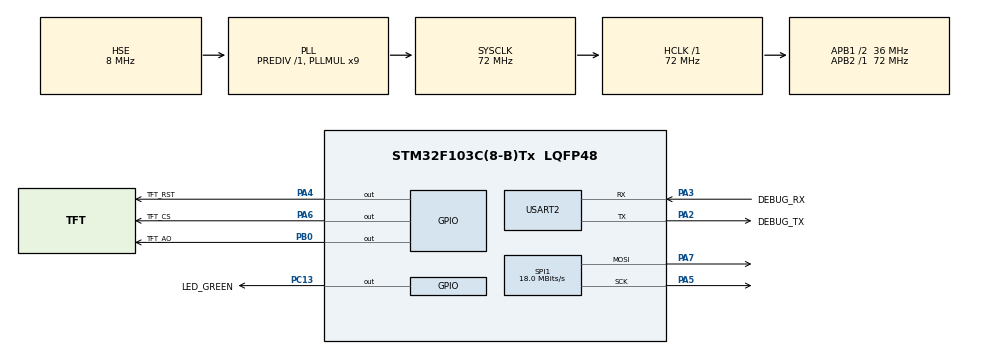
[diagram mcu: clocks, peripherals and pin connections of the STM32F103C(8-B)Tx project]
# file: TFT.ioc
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Mcu.Family=STM32F1
Mcu.Name=STM32F103C(8-B)Tx
Mcu.Package=LQFP48
NVIC.PriorityGroup=NVIC_PRIORITYGROUP_4
PA13.Mode=Serial_Wire
PA13.Signal=SYS_JTMS-SWDIO
PA14.Mode=Serial_Wire
PA14.Signal=SYS_JTCK-SWCLK
PA2.GPIO_Label=DEBUG_TX
PA2.Mode=Asynchronous
PA2.Signal=USART2_TX
PA3.GPIO_Label=DEBUG_RX
PA3.Mode=Asynchronous
PA3.Signal=USART2_RX
PA4.GPIO_Label=TFT_RST
PA4.GPIO_Speed=GPIO_SPEED_FREQ_HIGH
PA4.Signal=GPIO_Output
PA5.Mode=TX_Only_Simplex_Unidirect_Master
PA5.Signal=SPI1_SCK
PA6.GPIO_Label=TFT_CS
PA6.GPIO_Speed=GPIO_SPEED_FREQ_HIGH
PA6.Signal=GPIO_Output
PA7.Mode=TX_Only_Simplex_Unidirect_Master
PA7.Signal=SPI1_MOSI
PB0.GPIO_Label=TFT_AO
PB0.GPIO_Speed=GPIO_SPEED_FREQ_HIGH
PB0.Signal=GPIO_Output
PC13-TAMPER-RTC.GPIO_Label=LED_GREEN
PC13-TAMPER-RTC.GPIO_Speed=GPIO_SPEED_FREQ_HIGH
PC13-TAMPER-RTC.Signal=GPIO_Output
PC14-OSC32_IN.Mode=LSE-External-Oscillator
PC14-OSC32_IN.Signal=RCC_OSC32_IN
PC15-OSC32_OUT.Mode=LSE-External-Oscillator
PC15-OSC32_OUT.Signal=RCC_OSC32_OUT
PD0-OSC_IN.Mode=HSE-External-Oscillator
PD0-OSC_IN.Signal=RCC_OSC_IN
PD1-OSC_OUT.Mode=HSE-External-Oscillator
PD1-OSC_OUT.Signal=RCC_OSC_OUT
ProjectManager.HeapSize=0x200
ProjectManager.StackSize=0x400
ProjectManager.TargetToolchain=EWARM
RCC.AHBFreq_Value=72000000
RCC.APB1CLKDivider=RCC_HCLK_DIV2
RCC.APB1Freq_Value=36000000
RCC.APB1TimFreq_Value=72000000
RCC.APB2Freq_Value=72000000
RCC.APB2TimFreq_Value=72000000
RCC.HCLKFreq_Value=72000000
RCC.PLLMUL=RCC_PLL_MUL9
RCC.PLLSourceVirtual=RCC_PLLSOURCE_HSE
RCC.SYSCLKFreq_VALUE=72000000
RCC.SYSCLKSource=RCC_SYSCLKSOURCE_PLLCLK
RCC.USBFreq_Value=48000000
RCC.USBPrescaler=RCC_USBCLKSOURCE_PLL_DIV1_5
SPI1.BaudRatePrescaler=SPI_BAUDRATEPRESCALER_4
SPI1.CLKPhase=SPI_PHASE_2EDGE
SPI1.CLKPolarity=SPI_POLARITY_HIGH
SPI1.CalculateBaudRate=18.0 MBits/s
SPI1.Direction=SPI_DIRECTION_2LINES
SPI1.Mode=SPI_MODE_MASTER
SPI1.VirtualType=VM_MASTER
USART2.VirtualMode=VM_ASYNC
board=TFT

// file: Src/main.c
/**
  ******************************************************************************
  * @file           : main.c
  * @brief          : Main program body
  ******************************************************************************
  ** This notice applies to any and all portions of this file
  * that are not between comment pairs USER CODE BEGIN and
  * USER CODE END. Other portions of this file, whether
  * inserted by the user or by software development tools
  * are owned by their respective copyright owners.
  *
  * COPYRIGHT(c) 2018 STMicroelectronics
  *
  * Redistribution and use in source and binary forms, with or without modification,
  * are permitted provided that the following conditions are met:
  *   1. Redistributions of source code must retain the above copyright notice,
  *      this list of conditions and the following disclaimer.
  *   2. Redistributions in binary form must reproduce the above copyright notice,
  *      this list of conditions and the following disclaimer in the documentation
  *      and/or other materials provided with the distribution.
  *   3. Neither the name of STMicroelectronics nor the names of its contributors
  *      may be used to endorse or promote products derived from this software
  *      without specific prior written permission.
  *
  * THIS SOFTWARE IS PROVIDED BY THE COPYRIGHT HOLDERS AND CONTRIBUTORS "AS IS"
  * AND ANY EXPRESS OR IMPLIED WARRANTIES, INCLUDING, BUT NOT LIMITED TO, THE
  * IMPLIED WARRANTIES OF MERCHANTABILITY AND FITNESS FOR A PARTICULAR PURPOSE ARE
  * DISCLAIMED. IN NO EVENT SHALL THE COPYRIGHT HOLDER OR CONTRIBUTORS BE LIABLE
  * FOR ANY DIRECT, INDIRECT, INCIDENTAL, SPECIAL, EXEMPLARY, OR CONSEQUENTIAL
  * DAMAGES (INCLUDING, BUT NOT LIMITED TO, PROCUREMENT OF SUBSTITUTE GOODS OR
  * SERVICES; LOSS OF USE, DATA, OR PROFITS; OR BUSINESS INTERRUPTION) HOWEVER
  * CAUSED AND ON ANY THEORY OF LIABILITY, WHETHER IN CONTRACT, STRICT LIABILITY,
  * OR TORT (INCLUDING NEGLIGENCE OR OTHERWISE) ARISING IN ANY WAY OUT OF THE USE
  * OF THIS SOFTWARE, EVEN IF ADVISED OF THE POSSIBILITY OF SUCH DAMAGE.
  *
  ******************************************************************************
  */
#include "main.h"
#include "stm32f1xx_hal.h"

/* USER CODE BEGIN Includes */

#include "LCD.h"
/* USER CODE END Includes */

SPI_HandleTypeDef hspi1;

UART_HandleTypeDef huart2;

/* USER CODE BEGIN PV */
/* Private variables ---------------------------------------------------------*/

/* USER CODE END PV */

void SystemClock_Config(void);
static void MX_GPIO_Init(void);
static void MX_USART2_UART_Init(void);
static void MX_SPI1_Init(void);

/* USER CODE BEGIN PFP */
/* Private function prototypes -----------------------------------------------*/

/* USER CODE END PFP */

int main(void)
{

  /* MCU Configuration----------------------------------------------------------*/

  /* Reset of all peripherals, Initializes the Flash interface and the Systick. */
  HAL_Init();

  /* Configure the system clock */
  SystemClock_Config();

  /* Initialize all configured peripherals */
  MX_GPIO_Init();
  MX_USART2_UART_Init();
  MX_SPI1_Init();
  /* USER CODE BEGIN 2 */
  HAL_UART_Transmit(&huart2,"TFT LCD TEST",sizeof("TFT LCD TEST"),0xFFFF );
  LCD_Init();
  /* USER CODE END 2 */

  /* Infinite loop */
  while (1)
  {

  /* USER CODE BEGIN 3 */
  LCD_Clear(BLUE);
  HAL_Delay(1000);
  LCD_Clear(YELLOW);
  HAL_Delay(1000);
  LCD_Clear(RED);
  }
  /* USER CODE END 3 */

}

void SystemClock_Config(void)
{

  RCC_OscInitTypeDef RCC_OscInitStruct;
  RCC_ClkInitTypeDef RCC_ClkInitStruct;

    /**Initializes the CPU, AHB and APB busses clocks
    */
  RCC_OscInitStruct.OscillatorType = RCC_OSCILLATORTYPE_HSE;
  RCC_OscInitStruct.HSEState = RCC_HSE_ON;
  RCC_OscInitStruct.HSEPredivValue = RCC_HSE_PREDIV_DIV1;
  RCC_OscInitStruct.HSIState = RCC_HSI_ON;
  RCC_OscInitStruct.PLL.PLLState = RCC_PLL_ON;
  RCC_OscInitStruct.PLL.PLLSource = RCC_PLLSOURCE_HSE;
  RCC_OscInitStruct.PLL.PLLMUL = RCC_PLL_MUL9;
  if (HAL_RCC_OscConfig(&RCC_OscInitStruct) != HAL_OK)
  {
    _Error_Handler(__FILE__, __LINE__);
  }

    /**Initializes the CPU, AHB and APB busses clocks
    */
  RCC_ClkInitStruct.ClockType = RCC_CLOCKTYPE_HCLK|RCC_CLOCKTYPE_SYSCLK
                              |RCC_CLOCKTYPE_PCLK1|RCC_CLOCKTYPE_PCLK2;
  RCC_ClkInitStruct.SYSCLKSource = RCC_SYSCLKSOURCE_PLLCLK;
  RCC_ClkInitStruct.AHBCLKDivider = RCC_SYSCLK_DIV1;
  RCC_ClkInitStruct.APB1CLKDivider = RCC_HCLK_DIV2;
  RCC_ClkInitStruct.APB2CLKDivider = RCC_HCLK_DIV1;

  if (HAL_RCC_ClockConfig(&RCC_ClkInitStruct, FLASH_LATENCY_2) != HAL_OK)
  {
    _Error_Handler(__FILE__, __LINE__);
  }

    /**Configure the Systick interrupt time
    */
  HAL_SYSTICK_Config(HAL_RCC_GetHCLKFreq()/1000);

    /**Configure the Systick
    */
  HAL_SYSTICK_CLKSourceConfig(SYSTICK_CLKSOURCE_HCLK);

  /* SysTick_IRQn interrupt configuration */
  HAL_NVIC_SetPriority(SysTick_IRQn, 0, 0);
}

/* SPI1 init function */
static void MX_SPI1_Init(void)
{

  /* SPI1 parameter configuration*/
  hspi1.Instance = SPI1;
  hspi1.Init.Mode = SPI_MODE_MASTER;
  hspi1.Init.Direction = SPI_DIRECTION_2LINES;
  hspi1.Init.DataSize = SPI_DATASIZE_8BIT;
  hspi1.Init.CLKPolarity = SPI_POLARITY_HIGH;
  hspi1.Init.CLKPhase = SPI_PHASE_2EDGE;
  hspi1.Init.NSS = SPI_NSS_SOFT;
  hspi1.Init.BaudRatePrescaler = SPI_BAUDRATEPRESCALER_4;
  hspi1.Init.FirstBit = SPI_FIRSTBIT_MSB;
  hspi1.Init.TIMode = SPI_TIMODE_DISABLE;
  hspi1.Init.CRCCalculation = SPI_CRCCALCULATION_DISABLE;
  hspi1.Init.CRCPolynomial = 10;
  if (HAL_SPI_Init(&hspi1) != HAL_OK)
  {
    _Error_Handler(__FILE__, __LINE__);
  }

}

/* USART2 init function */
static void MX_USART2_UART_Init(void)
{

  huart2.Instance = USART2;
  huart2.Init.BaudRate = 115200;
  huart2.Init.WordLength = UART_WORDLENGTH_8B;
  huart2.Init.StopBits = UART_STOPBITS_1;
  huart2.Init.Parity = UART_PARITY_NONE;
  huart2.Init.Mode = UART_MODE_TX_RX;
  huart2.Init.HwFlowCtl = UART_HWCONTROL_NONE;
  huart2.Init.OverSampling = UART_OVERSAMPLING_16;
  if (HAL_UART_Init(&huart2) != HAL_OK)
  {
    _Error_Handler(__FILE__, __LINE__);
  }

}

/** Configure pins as
        * Analog
        * Input
        * Output
        * EVENT_OUT
        * EXTI
*/
static void MX_GPIO_Init(void)
{

  GPIO_InitTypeDef GPIO_InitStruct;

  /* GPIO Ports Clock Enable */
  __HAL_RCC_GPIOC_CLK_ENABLE();
  __HAL_RCC_GPIOD_CLK_ENABLE();
  __HAL_RCC_GPIOA_CLK_ENABLE();
  __HAL_RCC_GPIOB_CLK_ENABLE();

  /*Configure GPIO pin Output Level */
  HAL_GPIO_WritePin(LED_GREEN_GPIO_Port, LED_GREEN_Pin, GPIO_PIN_RESET);

  /*Configure GPIO pin Output Level */
  HAL_GPIO_WritePin(GPIOA, TFT_RST_Pin|TFT_CS_Pin, GPIO_PIN_RESET);

  /*Configure GPIO pin Output Level */
  HAL_GPIO_WritePin(TFT_AO_GPIO_Port, TFT_AO_Pin, GPIO_PIN_RESET);

  /*Configure GPIO pin : LED_GREEN_Pin */
  GPIO_InitStruct.Pin = LED_GREEN_Pin;
  GPIO_InitStruct.Mode = GPIO_MODE_OUTPUT_PP;
  GPIO_InitStruct.Speed = GPIO_SPEED_FREQ_HIGH;
  HAL_GPIO_Init(LED_GREEN_GPIO_Port, &GPIO_InitStruct);

  /*Configure GPIO pins : TFT_RST_Pin TFT_CS_Pin */
  GPIO_InitStruct.Pin = TFT_RST_Pin|TFT_CS_Pin;
  GPIO_InitStruct.Mode = GPIO_MODE_OUTPUT_PP;
  GPIO_InitStruct.Speed = GPIO_SPEED_FREQ_HIGH;
  HAL_GPIO_Init(GPIOA, &GPIO_InitStruct);

  /*Configure GPIO pin : TFT_AO_Pin */
  GPIO_InitStruct.Pin = TFT_AO_Pin;
  GPIO_InitStruct.Mode = GPIO_MODE_OUTPUT_PP;
  GPIO_InitStruct.Speed = GPIO_SPEED_FREQ_HIGH;
  HAL_GPIO_Init(TFT_AO_GPIO_Port, &GPIO_InitStruct);

}

void _Error_Handler(char *file, int line)
{
  while(1)
  {
  }
}

/************************ (C) COPYRIGHT STMicroelectronics *****END OF FILE****/
